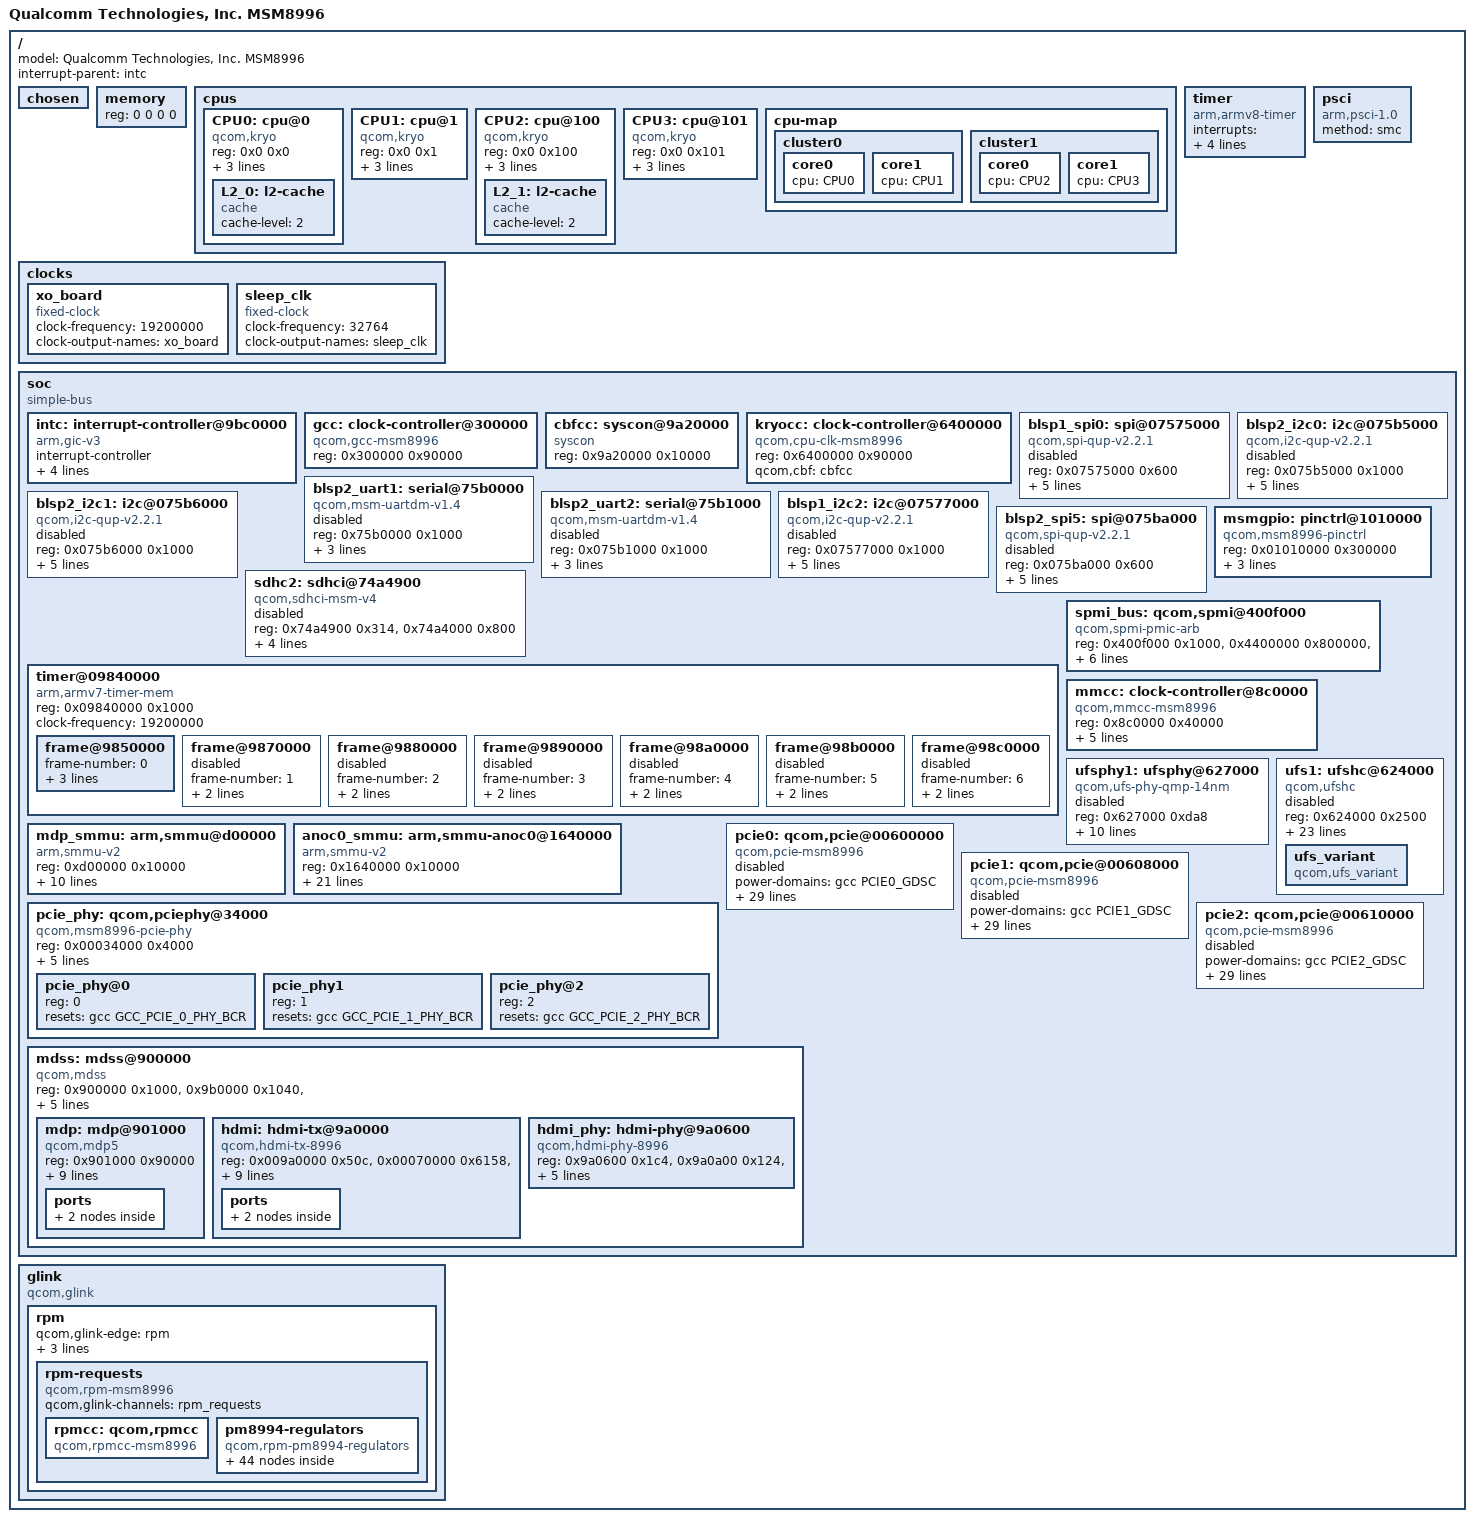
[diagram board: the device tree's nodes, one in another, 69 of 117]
/* Copyright (c) 2014-2015, The Linux Foundation. All rights reserved.
 *
 * This program is free software; you can redistribute it and/or modify
 * it under the terms of the GNU General Public License version 2 and
 * only version 2 as published by the Free Software Foundation.
 *
 * This program is distributed in the hope that it will be useful,
 * but WITHOUT ANY WARRANTY; without even the implied warranty of
 * MERCHANTABILITY or FITNESS FOR A PARTICULAR PURPOSE.  See the
 * GNU General Public License for more details.
 */

#include <dt-bindings/interrupt-controller/arm-gic.h>
#include <dt-bindings/clock/qcom,gcc-msm8996.h>
#include <dt-bindings/clock/qcom,mmcc-msm8996.h>
#include <dt-bindings/clock/qcom,rpmcc.h>

/ {
	model = "Qualcomm Technologies, Inc. MSM8996";

	interrupt-parent = <&intc>;

	#address-cells = <2>;
	#size-cells = <2>;

	chosen { };

	memory {
		device_type = "memory";
		/* We expect the bootloader to fill in the reg */
		reg = <0 0 0 0>;
	};

	cpus {
		#address-cells = <2>;
		#size-cells = <0>;

		CPU0: cpu@0 {
			device_type = "cpu";
			compatible = "qcom,kryo";
			reg = <0x0 0x0>;
			enable-method = "psci";
			clocks = <&kryocc 0>;
			next-level-cache = <&L2_0>;
			L2_0: l2-cache {
			      compatible = "cache";
			      cache-level = <2>;
			};
		};

		CPU1: cpu@1 {
			device_type = "cpu";
			compatible = "qcom,kryo";
			reg = <0x0 0x1>;
			enable-method = "psci";
			clocks = <&kryocc 0>;
			next-level-cache = <&L2_0>;
		};

		CPU2: cpu@100 {
			device_type = "cpu";
			compatible = "qcom,kryo";
			reg = <0x0 0x100>;
			enable-method = "psci";

			clocks = <&kryocc 1>;
			next-level-cache = <&L2_1>;
			L2_1: l2-cache {
			      compatible = "cache";
			      cache-level = <2>;
			};
		};

		CPU3: cpu@101 {
			device_type = "cpu";
			compatible = "qcom,kryo";
			reg = <0x0 0x101>;
			enable-method = "psci";
			clocks = <&kryocc 1>;
			next-level-cache = <&L2_1>;
		};

		cpu-map {
			cluster0 {
				core0 {
					cpu = <&CPU0>;
				};

				core1 {
					cpu = <&CPU1>;
				};
			};

			cluster1 {
				core0 {
					cpu = <&CPU2>;
				};

				core1 {
					cpu = <&CPU3>;
				};
			};
		};
	};

	timer {
		compatible = "arm,armv8-timer";
		interrupts = <GIC_PPI 13 (GIC_CPU_MASK_SIMPLE(4) | IRQ_TYPE_LEVEL_LOW)>,
			     <GIC_PPI 14 (GIC_CPU_MASK_SIMPLE(4) | IRQ_TYPE_LEVEL_LOW)>,
			     <GIC_PPI 11 (GIC_CPU_MASK_SIMPLE(4) | IRQ_TYPE_LEVEL_LOW)>,
			     <GIC_PPI 10 (GIC_CPU_MASK_SIMPLE(4) | IRQ_TYPE_LEVEL_LOW)>;
	};

	clocks {
		xo_board {
			compatible = "fixed-clock";
			#clock-cells = <0>;
			clock-frequency = <19200000>;
			clock-output-names = "xo_board";
		};

		sleep_clk {
			compatible = "fixed-clock";
			#clock-cells = <0>;
			clock-frequency = <32764>;
			clock-output-names = "sleep_clk";
		};

	};

	psci {
		compatible = "arm,psci-1.0";
		method = "smc";
	};

	soc: soc {
		#address-cells = <1>;
		#size-cells = <1>;
		ranges = <0 0 0 0xffffffff>;
		compatible = "simple-bus";

		intc: interrupt-controller@9bc0000 {
			compatible = "arm,gic-v3";
			#interrupt-cells = <3>;
			interrupt-controller;
			#redistributor-regions = <1>;
			redistributor-stride = <0x0 0x40000>;
			reg = <0x09bc0000 0x10000>,
			      <0x09c00000 0x100000>;
			interrupts = <GIC_PPI 9 IRQ_TYPE_LEVEL_HIGH>;
		};

		gcc: clock-controller@300000 {
			compatible = "qcom,gcc-msm8996";
			#clock-cells = <1>;
			#reset-cells = <1>;
			#power-domain-cells = <1>;
			reg = <0x300000 0x90000>;
		};

		cbfcc: syscon@9a20000 {
			compatible = "syscon";
			reg = <0x9a20000 0x10000>;
		};

		kryocc: clock-controller@6400000 {
			compatible = "qcom,cpu-clk-msm8996";
			reg = <0x6400000 0x90000>;
			#clock-cells = <1>;
			qcom,cbf = <&cbfcc>;
		};

		blsp1_spi0: spi@07575000 {
			compatible = "qcom,spi-qup-v2.2.1";
			reg = <0x07575000 0x600>;
			interrupts = <GIC_SPI 95 IRQ_TYPE_LEVEL_HIGH>;
			clocks = <&gcc GCC_BLSP1_QUP1_SPI_APPS_CLK>,
				 <&gcc GCC_BLSP1_AHB_CLK>;
			clock-names = "core", "iface";
			pinctrl-names = "default", "sleep";
			pinctrl-0 = <&blsp1_spi0_default>;
			pinctrl-1 = <&blsp1_spi0_sleep>;
			#address-cells = <1>;
			#size-cells = <0>;
			status = "disabled";
		};

		blsp2_i2c0: i2c@075b5000 {
			compatible = "qcom,i2c-qup-v2.2.1";
			reg = <0x075b5000 0x1000>;
			interrupts = <GIC_SPI 101 0>;
			clocks = <&gcc GCC_BLSP2_AHB_CLK>,
				<&gcc GCC_BLSP2_QUP1_I2C_APPS_CLK>;
			clock-names = "iface", "core";
			pinctrl-names = "default", "sleep";
			pinctrl-0 = <&blsp2_i2c0_default>;
			pinctrl-1 = <&blsp2_i2c0_sleep>;
			#address-cells = <1>;
			#size-cells = <0>;
			status = "disabled";
		};

		blsp2_uart1: serial@75b0000 {
			compatible = "qcom,msm-uartdm-v1.4", "qcom,msm-uartdm";
			reg = <0x75b0000 0x1000>;
			interrupts = <GIC_SPI 114 IRQ_TYPE_LEVEL_HIGH>;
			clocks = <&gcc GCC_BLSP2_UART2_APPS_CLK>,
				 <&gcc GCC_BLSP2_AHB_CLK>;
			clock-names = "core", "iface";
			status = "disabled";
		};

		blsp2_i2c1: i2c@075b6000 {
			compatible = "qcom,i2c-qup-v2.2.1";
			reg = <0x075b6000 0x1000>;
			interrupts = <GIC_SPI 102 0>;
			clocks = <&gcc GCC_BLSP2_AHB_CLK>,
				<&gcc GCC_BLSP2_QUP2_I2C_APPS_CLK>;
			clock-names = "iface", "core";
			pinctrl-names = "default", "sleep";
			pinctrl-0 = <&blsp2_i2c1_default>;
			pinctrl-1 = <&blsp2_i2c1_sleep>;
			#address-cells = <1>;
			#size-cells = <0>;
			status = "disabled";
		};

		blsp2_uart2: serial@75b1000 {
			compatible = "qcom,msm-uartdm-v1.4", "qcom,msm-uartdm";
			reg = <0x075b1000 0x1000>;
			interrupts = <GIC_SPI 115 IRQ_TYPE_LEVEL_HIGH>;
			clocks = <&gcc GCC_BLSP2_UART3_APPS_CLK>,
				 <&gcc GCC_BLSP2_AHB_CLK>;
			clock-names = "core", "iface";
			status = "disabled";
		};

		blsp1_i2c2: i2c@07577000 {
			compatible = "qcom,i2c-qup-v2.2.1";
			reg = <0x07577000 0x1000>;
			interrupts = <GIC_SPI 97 0>;
			clocks = <&gcc GCC_BLSP1_AHB_CLK>,
				<&gcc GCC_BLSP1_QUP3_I2C_APPS_CLK>;
			clock-names = "iface", "core";
			pinctrl-names = "default", "sleep";
			pinctrl-0 = <&blsp1_i2c2_default>;
			pinctrl-1 = <&blsp1_i2c2_sleep>;
			#address-cells = <1>;
			#size-cells = <0>;
			status = "disabled";
		};

		blsp2_spi5: spi@075ba000{
			compatible = "qcom,spi-qup-v2.2.1";
			reg = <0x075ba000 0x600>;
			interrupts = <GIC_SPI 107 IRQ_TYPE_LEVEL_HIGH>;
			clocks = <&gcc GCC_BLSP2_QUP5_SPI_APPS_CLK>,
				 <&gcc GCC_BLSP2_AHB_CLK>;
			clock-names = "core", "iface";
			pinctrl-names = "default", "sleep";
			pinctrl-0 = <&blsp2_spi5_default>;
			pinctrl-1 = <&blsp2_spi5_sleep>;
			#address-cells = <1>;
			#size-cells = <0>;
			status = "disabled";
		};

		sdhc2: sdhci@74a4900 {
			 status = "disabled";
			 compatible = "qcom,sdhci-msm-v4";
			 reg = <0x74a4900 0x314>, <0x74a4000 0x800>;
			 reg-names = "hc_mem", "core_mem";

			 interrupts = <0 125 0>, <0 221 0>;
			 interrupt-names = "hc_irq", "pwr_irq";

			 clock-names = "iface", "core";
			 clocks = <&gcc GCC_SDCC2_AHB_CLK>,
			 <&gcc GCC_SDCC2_APPS_CLK>;
			 bus-width = <4>;
		 };

		msmgpio: pinctrl@1010000 {
			compatible = "qcom,msm8996-pinctrl";
			reg = <0x01010000 0x300000>;
			interrupts = <GIC_SPI 208 IRQ_TYPE_LEVEL_HIGH>;
			gpio-controller;
			#gpio-cells = <2>;
			interrupt-controller;
			#interrupt-cells = <2>;
		};

		timer@09840000 {
			#address-cells = <1>;
			#size-cells = <1>;
			ranges;
			compatible = "arm,armv7-timer-mem";
			reg = <0x09840000 0x1000>;
			clock-frequency = <19200000>;

			frame@9850000 {
				frame-number = <0>;
				interrupts = <GIC_SPI 31 IRQ_TYPE_LEVEL_HIGH>,
					     <GIC_SPI 30 IRQ_TYPE_LEVEL_HIGH>;
				reg = <0x09850000 0x1000>,
				      <0x09860000 0x1000>;
			};

			frame@9870000 {
				frame-number = <1>;
				interrupts = <GIC_SPI 32 IRQ_TYPE_LEVEL_HIGH>;
				reg = <0x09870000 0x1000>;
				status = "disabled";
			};

			frame@9880000 {
				frame-number = <2>;
				interrupts = <GIC_SPI 33 IRQ_TYPE_LEVEL_HIGH>;
				reg = <0x09880000 0x1000>;
				status = "disabled";
			};

			frame@9890000 {
				frame-number = <3>;
				interrupts = <GIC_SPI 34 IRQ_TYPE_LEVEL_HIGH>;
				reg = <0x09890000 0x1000>;
				status = "disabled";
			};

			frame@98a0000 {
				frame-number = <4>;
				interrupts = <GIC_SPI 35 IRQ_TYPE_LEVEL_HIGH>;
				reg = <0x098a0000 0x1000>;
				status = "disabled";
			};

			frame@98b0000 {
				frame-number = <5>;
				interrupts = <GIC_SPI 36 IRQ_TYPE_LEVEL_HIGH>;
				reg = <0x098b0000 0x1000>;
				status = "disabled";
			};

			frame@98c0000 {
				frame-number = <6>;
				interrupts = <GIC_SPI 37 IRQ_TYPE_LEVEL_HIGH>;
				reg = <0x098c0000 0x1000>;
				status = "disabled";
			};
		};

		spmi_bus: qcom,spmi@400f000 {
			compatible = "qcom,spmi-pmic-arb";
			reg = <0x400f000 0x1000>,
			      <0x4400000 0x800000>,
			      <0x4c00000 0x800000>,
			      <0x5800000 0x200000>,
			      <0x400a000 0x002100>;
			reg-names = "core", "chnls", "obsrvr", "intr", "cnfg";
			interrupt-names = "periph_irq";
			interrupts = <GIC_SPI 326 IRQ_TYPE_NONE>;
			qcom,ee = <0>;
			qcom,channel = <0>;
			#address-cells = <2>;
			#size-cells = <0>;
			interrupt-controller;
			#interrupt-cells = <4>;
		};

		mmcc: clock-controller@8c0000 {
			compatible = "qcom,mmcc-msm8996";
			#clock-cells = <1>;
			#reset-cells = <1>;
			#power-domain-cells = <1>;
			reg = <0x8c0000 0x40000>;
			assigned-clocks = <&mmcc MMPLL9_PLL>,
					  <&mmcc MMPLL1_PLL>,
					  <&mmcc MMPLL3_PLL>,
					  <&mmcc MMPLL4_PLL>,
					  <&mmcc MMPLL5_PLL>;
			assigned-clock-rates = <624000000>,
					       <810000000>,
					       <980000000>,
					       <960000000>,
					       <825000000>;
		};

		ufsphy1: ufsphy@627000 {
			compatible = "qcom,ufs-phy-qmp-14nm";
			reg = <0x627000 0xda8>;
			reg-names = "phy_mem";
			#phy-cells = <0>;

			vdda-phy-supply = <&pm8994_l28>;
			vdda-pll-supply = <&pm8994_l12>;

			vdda-phy-max-microamp = <18380>;
			vdda-pll-max-microamp = <9440>;

			vddp-ref-clk-supply = <&pm8994_l25>;
			vddp-ref-clk-max-microamp = <100>;
			vddp-ref-clk-always-on;
			clock-names = "ref_clk_src", "ref_clk";
			clocks = <&rpmcc MSM8996_RPM_SMD_LN_BB_CLK>,
				 <&gcc GCC_UFS_CLKREF_CLK>;
			power-domains = <&gcc UFS_GDSC>;
			status = "disabled";
		};

		ufs1: ufshc@624000 {
			compatible = "qcom,ufshc";
			reg = <0x624000 0x2500>;
			interrupts = <0 265 0>;
			phys = <&ufsphy1>;
			phy-names = "ufsphy";

			vcc-supply = <&pm8994_l20>;
			vccq-supply = <&pm8994_l25>;
			vccq2-supply = <&pm8994_s4>;

			vcc-max-microamp = <600000>;
			vccq-max-microamp = <450000>;
			vccq2-max-microamp = <450000>;

			clock-names =
				"core_clk_src",
				"core_clk",
				"bus_clk",
				"bus_aggr_clk",
				"iface_clk",
				"core_clk_unipro_src",
				"core_clk_unipro",
				"core_clk_ice",
				"ref_clk",
				"tx_lane0_sync_clk",
				"rx_lane0_sync_clk";
			clocks =
				<&gcc UFS_AXI_CLK_SRC>,
				<&gcc GCC_UFS_AXI_CLK>,
				<&gcc GCC_SYS_NOC_UFS_AXI_CLK>,
				<&gcc GCC_AGGRE2_UFS_AXI_CLK>,
				<&gcc GCC_UFS_AHB_CLK>,
				<&gcc UFS_ICE_CORE_CLK_SRC>,
				<&gcc GCC_UFS_UNIPRO_CORE_CLK>,
				<&gcc GCC_UFS_ICE_CORE_CLK>,
				<&rpmcc MSM8996_RPM_SMD_LN_BB_CLK>,
				<&gcc GCC_UFS_TX_SYMBOL_0_CLK>,
				<&gcc GCC_UFS_RX_SYMBOL_0_CLK>;
			freq-table-hz =
				<100000000 200000000>,
				<0 0>,
				<0 0>,
				<0 0>,
				<0 0>,
				<150000000 300000000>,
				<0 0>,
				<0 0>,
				<0 0>,
				<0 0>,
				<0 0>;

			lanes-per-direction = <1>;
			status = "disabled";

			ufs_variant {
				compatible = "qcom,ufs_variant";
			};
		};

		mdp_smmu: arm,smmu@d00000 {
			compatible = "arm,smmu-v2";
			reg = <0xd00000 0x10000>;

			#global-interrupts = <1>;
			interrupts = <0 73 0>,
				     <0 320 0>,
				     <0 321 0>;
			#iommu-cells = <1>;

			clocks = <&mmcc MMSS_MMAGIC_AHB_CLK>,
				 <&mmcc MMSS_MMAGIC_CFG_AHB_CLK>,
				 <&mmcc SMMU_MDP_AHB_CLK>,
				 <&mmcc SMMU_MDP_AXI_CLK>,
				 <&mmcc MMAGIC_MDSS_AXI_CLK>,
				 <&mmcc MMSS_MISC_AHB_CLK>;
			clock-names = "mmagic_iface_clk",
				"mmagic_cfg_iface_clk",
				"smmu_iface_clk",
				"smmu_bus_clk",
				"mmagic_mdss_bus_clk",
				"mmss_misc_bus_clk";

			qcom,skip-init;
			qcom,no-smr-check;

			status = "okay";
		};

		anoc0_smmu: arm,smmu-anoc0@1640000 {
			compatible = "arm,smmu-v2";
			reg = <0x1640000 0x10000>;
			power-domains = <&gcc AGGRE0_NOC_GDSC>;
			status = "okay";

			#global-interrupts = <1>;
			interrupts = <0 362 0>,
				     <0 355 0>,
				     <0 356 0>,
				     <0 357 0>,
				     <0 358 0>,
				     <0 359 0>,
				     <0 360 0>;
			#iommu-cells = <0>;
			#clock-cells = <1>;

			clocks = <&gcc GCC_SMMU_AGGRE0_AXI_CLK>,
				 <&gcc GCC_SMMU_AGGRE0_AHB_CLK>;
			clock-names = "smmu_aggre0_axi_clk",
				      "smmu_aggre0_ahb_clk";
			qcom,skip-init;
			qcom,register-save;
			attach-impl-defs = <0x6000 0x70>,
				<0x6060 0x1055>,
				<0x6070 0x8>,
				<0x6074 0x30>,
				<0x6078 0x40>,
				<0x6170 0x0>,
				<0x6174 0x3>,
				<0x6178 0x5>,
				<0x6270 0x0>,
				<0x6274 0x0>,
				<0x6278 0x0>,
				<0x6470 0x0>,
				<0x6474 0x2>,
				<0x6478 0x4>,
				<0x6570 0x6>,
				<0x6574 0x12>,
				<0x6578 0x1c>,
				<0x6670 0x26>,
				<0x6674 0x30>,
				<0x6678 0x40>,
				<0x67a0 0x0>,
				<0x67a4 0x58>,
				<0x67a8 0x60>,
				<0x67b0 0x0>,
				<0x67b4 0x6>,
				<0x67b8 0x86>,
				<0x67d0 0x0>,
				<0x67dc 0x4>,
				<0x67e0 0x4>,
				<0x6800 0x0>,
				<0x6804 0x1>,
				<0x6808 0x2>,
				<0x680c 0x0>,
				<0x6a00 0x6>,
				<0x6b00 0x3ff>,
				<0x6d30 0x41bd>,
				<0x6784 0x0>,
				<0x678c 0x10>;
		};

		pcie_phy: qcom,pciephy@34000 {
			compatible = "qcom,msm8996-pcie-phy";
			#phy-cells = <1>;
			reg = <0x00034000 0x4000>;
			resets = <&gcc GCC_PCIE_PHY_BCR>,
				<&gcc GCC_PCIE_PHY_COM_BCR>,
				<&gcc GCC_PCIE_PHY_COM_NOCSR_BCR>;
			reset-names = "phy_com",  "phy_com2", "phy_cfg";
	
			clocks = <&gcc GCC_PCIE_PHY_CFG_AHB_CLK>,
				<&gcc GCC_PCIE_PHY_AUX_CLK>;
			clock-names = "cfg", "aux";
	
			#address-cells = <1>;
			#size-cells = <0>;
			pcie_phy@0{
				reg = <0>;
				resets = <&gcc GCC_PCIE_0_PHY_BCR>;
				reset-names = "phy";
			};
	
			pcie_phy1{
				reg = <1>;
				resets = <&gcc GCC_PCIE_1_PHY_BCR>;
				reset-names = "phy";
			};
	
			pcie_phy@2{
				reg = <2>;
				resets = <&gcc GCC_PCIE_2_PHY_BCR>;
				reset-names = "phy";
			};
		};
	
		pcie0: qcom,pcie@00600000 {
			compatible = "qcom,pcie-msm8996", "snps,dw-pcie";
			status = "disabled";
			power-domains = <&gcc PCIE0_GDSC>;
			bus-range = <0x00 0xff>;
			num-lanes = <1>;
	
			reg = <0x00600000 0x2000>,
			      <0x0c000000 0xf1d>,
			      <0x0c000f20 0xa8>,
			      <0x0c100000 0x100000>;
			reg-names = "parf", "dbi", "elbi","config";
	
			phys = <&pcie_phy 0>;
			phy-names = "pciephy";
	
			#address-cells = <3>;
			#size-cells = <2>;
			ranges = <0x01000000 0x0 0x0c200000 0x0c200000 0x0 0x100000>,
				<0x02000000 0x0 0x0c300000 0x0c300000 0x0 0xd00000>;
	
			interrupts = <GIC_SPI 405 IRQ_TYPE_NONE>;
			interrupt-names = "msi";
			#interrupt-cells = <1>;
			interrupt-map-mask = <0 0 0 0x7>;
			interrupt-map = <0 0 0 1 &intc 0 244 IRQ_TYPE_LEVEL_HIGH>, /* int_a */
					<0 0 0 2 &intc 0 245 IRQ_TYPE_LEVEL_HIGH>, /* int_b */
					<0 0 0 3 &intc 0 247 IRQ_TYPE_LEVEL_HIGH>, /* int_c */
					<0 0 0 4 &intc 0 248 IRQ_TYPE_LEVEL_HIGH>; /* int_d */
	
			pinctrl-names = "default", "sleep";
			pinctrl-0 = <&pcie0_clkreq_default &pcie0_perst_default &pcie0_wake_default>;
			pinctrl-1 = <&pcie0_clkreq_sleep &pcie0_perst_default &pcie0_wake_sleep>;
	
	
			vreg-1.8-supply = <&pm8994_l12>;
			vreg-0.9-supply = <&pm8994_l28>;
	
			iommus = <&anoc0_smmu>;
			linux,pci-domain = <0>;
	
			clocks = <&gcc GCC_PCIE_0_PIPE_CLK>,
				<&rpmcc MSM8996_RPM_SMD_LN_BB_CLK>,
				<&gcc GCC_PCIE_0_AUX_CLK>,
				<&gcc GCC_PCIE_0_CFG_AHB_CLK>,
				<&gcc GCC_PCIE_0_MSTR_AXI_CLK>,
				<&gcc GCC_PCIE_0_SLV_AXI_CLK>,
				<&gcc GCC_PCIE_CLKREF_CLK>,
				<&gcc GCC_AGGRE0_SNOC_AXI_CLK>,
				<&gcc GCC_AGGRE0_CNOC_AHB_CLK>;
	
			clock-names =  "pipe",
					"bus",
					"aux",
					"cfg",
					"master",
					"slave",
					"ref",
					"axi",
					"ahb";
		};
	
	
		pcie1: qcom,pcie@00608000 {
			compatible = "qcom,pcie-msm8996", "snps,dw-pcie";
			power-domains = <&gcc PCIE1_GDSC>;
			bus-range = <0x00 0xff>;
			num-lanes = <1>;
	
			status  = "disabled";
	
			reg = <0x00608000 0x2000>,
			      <0x0d000000 0xf1d>,
			      <0x0d000f20 0xa8>,
			      <0x0d100000 0x100000>;
	
			reg-names = "parf", "dbi", "elbi","config";
	
			phys = <&pcie_phy 1>;
			phy-names = "pciephy";
	
			#address-cells = <3>;
			#size-cells = <2>;
			ranges = <0x01000000 0x0 0x0d200000 0x0d200000 0x0 0x100000>,
				<0x02000000 0x0 0x0d300000 0x0d300000 0x0 0xd00000>;
	
			interrupts = <GIC_SPI 413 IRQ_TYPE_NONE>;
			interrupt-names = "msi";
			#interrupt-cells = <1>;
			interrupt-map-mask = <0 0 0 0x7>;
			interrupt-map = <0 0 0 1 &intc 0 272 IRQ_TYPE_LEVEL_HIGH>, /* int_a */
					<0 0 0 2 &intc 0 273 IRQ_TYPE_LEVEL_HIGH>, /* int_b */
					<0 0 0 3 &intc 0 274 IRQ_TYPE_LEVEL_HIGH>, /* int_c */
					<0 0 0 4 &intc 0 275 IRQ_TYPE_LEVEL_HIGH>; /* int_d */
	
			pinctrl-names = "default", "sleep";
			pinctrl-0 = <&pcie1_clkreq_default &pcie1_perst_default &pcie1_wake_default>;
			pinctrl-1 = <&pcie1_clkreq_sleep &pcie1_perst_default &pcie1_wake_sleep>;
	
	
			vreg-1.8-supply = <&pm8994_l12>;
			vreg-0.9-supply = <&pm8994_l28>;
			iommus = <&anoc0_smmu>;
	
			linux,pci-domain = <1>;
	
			clocks = <&gcc GCC_PCIE_1_PIPE_CLK>,
				<&rpmcc MSM8996_RPM_SMD_LN_BB_CLK>,
				<&gcc GCC_PCIE_1_AUX_CLK>,
				<&gcc GCC_PCIE_1_CFG_AHB_CLK>,
				<&gcc GCC_PCIE_1_MSTR_AXI_CLK>,
				<&gcc GCC_PCIE_1_SLV_AXI_CLK>,
				<&gcc GCC_PCIE_CLKREF_CLK>,
				<&gcc GCC_AGGRE0_SNOC_AXI_CLK>,
				<&gcc GCC_AGGRE0_CNOC_AHB_CLK>;
	
			clock-names =  "pipe",
					"bus",
					"aux",
					"cfg",
					"master",
					"slave",
					"ref",
					"axi",
					"ahb";
	
		};
	
		pcie2: qcom,pcie@00610000 {
			compatible = "qcom,pcie-msm8996", "snps,dw-pcie";
			power-domains = <&gcc PCIE2_GDSC>;
			bus-range = <0x00 0xff>;
			num-lanes = <1>;
			status = "disabled";
			reg = <0x00610000 0x2000>,
			      <0x0e000000 0xf1d>,
			      <0x0e000f20 0xa8>,
			      <0x0e100000 0x100000>;
	
			reg-names = "parf", "dbi", "elbi","config";
	
			phys = <&pcie_phy 2>;
			phy-names = "pciephy";
	
			#address-cells = <3>;
			#size-cells = <2>;
			ranges = <0x01000000 0x0 0x0e200000 0x0e200000 0x0 0x100000>,
				<0x02000000 0x0 0x0e300000 0x0e300000 0x0 0x1d00000>;
			
			device_type = "pci";
	
			interrupts = <GIC_SPI 421 IRQ_TYPE_NONE>;
			interrupt-names = "msi";
			#interrupt-cells = <1>;
			interrupt-map-mask = <0 0 0 0x7>;
			interrupt-map = <0 0 0 1 &intc 0 142 IRQ_TYPE_LEVEL_HIGH>, /* int_a */
					<0 0 0 2 &intc 0 143 IRQ_TYPE_LEVEL_HIGH>, /* int_b */
					<0 0 0 3 &intc 0 144 IRQ_TYPE_LEVEL_HIGH>, /* int_c */
					<0 0 0 4 &intc 0 145 IRQ_TYPE_LEVEL_HIGH>; /* int_d */
	
			pinctrl-names = "default", "sleep";
			pinctrl-0 = <&pcie2_clkreq_default &pcie2_perst_default &pcie2_wake_default>;
			pinctrl-1 = <&pcie2_clkreq_sleep &pcie2_perst_default &pcie2_wake_sleep >;
	
			vreg-1.8-supply = <&pm8994_l12>;
			vreg-0.9-supply = <&pm8994_l28>;
			iommus = <&anoc0_smmu>;
	
			linux,pci-domain = <2>;
			clocks = <&gcc GCC_PCIE_2_PIPE_CLK>,
				<&rpmcc MSM8996_RPM_SMD_LN_BB_CLK>,
				<&gcc GCC_PCIE_2_AUX_CLK>,
				<&gcc GCC_PCIE_2_CFG_AHB_CLK>,
				<&gcc GCC_PCIE_2_MSTR_AXI_CLK>,
				<&gcc GCC_PCIE_2_SLV_AXI_CLK>,
				<&gcc GCC_PCIE_CLKREF_CLK>,
				<&gcc GCC_AGGRE0_SNOC_AXI_CLK>,
				<&gcc GCC_AGGRE0_CNOC_AHB_CLK>;
	
			clock-names =  "pipe",
					"bus",
					"aux",
					"cfg",
					"master",
					"slave",
					"ref",
					"axi",
					"ahb";
		};

		mdss: mdss@900000 {
			compatible = "qcom,mdss";

			reg = <0x900000 0x1000>,
			      <0x9b0000 0x1040>,
			      <0x9b8000 0x1040>;
			reg-names = "mdss_phys",
				    "vbif_phys",
				    "vbif_nrt_phys";

			power-domains = <&mmcc MDSS_GDSC>;
			interrupts = <0 83 0>;

			interrupt-controller;
			#interrupt-cells = <1>;

			clocks = <&mmcc MDSS_AHB_CLK>;
			clock-names = "iface_clk";

			#address-cells = <1>;
			#size-cells = <1>;
			ranges;

			mdp: mdp@901000 {
				compatible = "qcom,mdp5";
				reg = <0x901000 0x90000>;
				reg-names = "mdp_phys";

				interrupt-parent = <&mdss>;
				interrupts = <0 0>;

				clocks = <&mmcc MDSS_AHB_CLK>,
					 <&mmcc MMSS_MMAGIC_AHB_CLK>,
					 <&mmcc MDSS_AXI_CLK>,
					 <&mmcc MDP_CLK_SRC>,
					 <&mmcc MDSS_MDP_CLK>,
					 <&mmcc SMMU_MDP_AXI_CLK>,
					 <&mmcc MDSS_VSYNC_CLK>,
					 <&mmcc MMAGIC_MDSS_AXI_CLK>,
					 <&rpmcc MSM8996_RPM_SMD_MMAXI_CLK>;
				clock-names = "iface_clk",
					      "mmagic_iface_clk",
					      "bus_clk",
					      "core_clk_src",
					      "core_clk",
					      "iommu_clk",
					      "vsync_clk",
					      "mmagic_mdss_bus_clk",
					      "rpm_mmaxi_clk";

				iommus = <&mdp_smmu 0>;

				ports {
					#address-cells = <1>;
					#size-cells = <0>;

					port@0 {
						reg = <0>;
						mdp5_intf3_out: endpoint {
							remote-endpoint = <&hdmi_in>;
						};
					};
				};
			};

			hdmi: hdmi-tx@9a0000 {
				compatible = "qcom,hdmi-tx-8996";
				reg =	<0x009a0000 0x50c>,
					<0x00070000 0x6158>,
					<0x009e0000 0xfff>;
				reg-names = "core_physical",
					    "qfprom_physical",
					    "hdcp_physical";

				interrupt-parent = <&mdss>;
				interrupts = <8 0>;

				power-domains = <&mmcc MDSS_GDSC>;
				clocks = <&mmcc MDSS_MDP_CLK>,
					 <&mmcc MMSS_MMAGIC_AHB_CLK>,
					 <&mmcc MDSS_AHB_CLK>,
					 <&mmcc MDSS_HDMI_CLK>,
					 <&mmcc MDSS_HDMI_AHB_CLK>,
					 <&mmcc MDSS_EXTPCLK_CLK>;
				clock-names =
					"mdp_core_clk",
					"mmagic_iface_clk",
					"iface_clk",
					"core_clk",
					"alt_iface_clk",
					"extp_clk";

				phys = <&hdmi_phy>;
				phy-names = "hdmi_phy";

				ports {
					#address-cells = <1>;
					#size-cells = <0>;

					port@0 {
						reg = <0>;
						hdmi_in: endpoint {
							remote-endpoint = <&mdp5_intf3_out>;
						};
					};
				};
			};

			hdmi_phy: hdmi-phy@9a0600 {
				compatible = "qcom,hdmi-phy-8996";
				reg = <0x9a0600 0x1c4>,
				      <0x9a0a00 0x124>,
				      <0x9a0c00 0x124>,
				      <0x9a0e00 0x124>,
				      <0x9a1000 0x124>,
				      <0x9a1200 0x0c8>;
				reg-names = "hdmi_pll",
					    "hdmi_tx_l0",
					    "hdmi_tx_l1",
					    "hdmi_tx_l2",
					    "hdmi_tx_l3",
					    "hdmi_phy";

				clocks = <&mmcc MDSS_AHB_CLK>,
					 <&mmcc MMSS_MMAGIC_AHB_CLK>,
					 <&gcc GCC_HDMI_CLKREF_CLK>;
				clock-names = "iface_clk",
					      "mmagic_iface_clk",
					      "ref_clk";
			};
		};
	};

	glink {
		compatible = "qcom,glink";
		#address-cells = <1>;
		#size-cells = <1>;
		ranges = <0 0 0 0xffffffff>;

		rpm {
			qcom,glink-edge = "rpm";
			interrupts = <0 168 1>;
			qcom,irq-mask = <0x1>;
			reg = <0x00068000 0x6000>,
			      <0x09820010 0x4>;
			reg-names = "msgram", "irq-reg-base";

			rpm-requests {
				compatible = "qcom,rpm-msm8996";
				qcom,glink-channels = "rpm_requests";

				rpmcc: qcom,rpmcc {
					compatible = "qcom,rpmcc-msm8996", "qcom,rpmcc";
					#clock-cells = <1>;
				};

				pm8994-regulators {
					compatible = "qcom,rpm-pm8994-regulators";

					pm8994_s1: s1 {};
					pm8994_s2: s2 {};
					pm8994_s3: s3 {};
					pm8994_s4: s4 {};
					pm8994_s5: s5 {};
					pm8994_s6: s6 {};
					pm8994_s7: s7 {};
					pm8994_s8: s8 {};
					pm8994_s9: s9 {};
					pm8994_s10: s10 {};
					pm8994_s11: s11 {};
					pm8994_s12: s12 {};

					pm8994_l1: l1 {};
					pm8994_l2: l2 {};
					pm8994_l3: l3 {};
					pm8994_l4: l4 {};
					pm8994_l5: l5 {};
					pm8994_l6: l6 {};
					pm8994_l7: l7 {};
					pm8994_l8: l8 {};
					pm8994_l9: l9 {};
					pm8994_l10: l10 {};
					pm8994_l11: l11 {};
					pm8994_l12: l12 {};
					pm8994_l13: l13 {};
					pm8994_l14: l14 {};
					pm8994_l15: l15 {};
					pm8994_l16: l16 {};
					pm8994_l17: l17 {};
					pm8994_l18: l18 {};
					pm8994_l19: l19 {};
					pm8994_l20: l20 {};
					pm8994_l21: l21 {};
					pm8994_l22: l22 {};
					pm8994_l23: l23 {};
					pm8994_l24: l24 {};
					pm8994_l25: l25 {};
					pm8994_l26: l26 {};
					pm8994_l27: l27 {};
					pm8994_l28: l28 {};
					pm8994_l29: l29 {};
					pm8994_l30: l30 {};
					pm8994_l31: l31 {};
					pm8994_l32: l32 {};
				};
			};
		};
	};
};
#include "msm8996-pins.dtsi"
